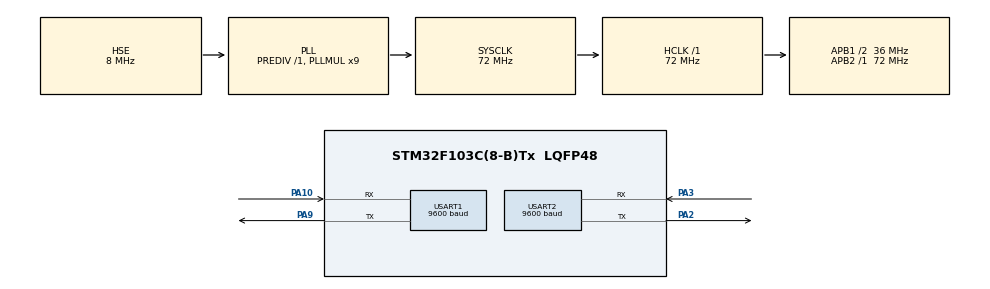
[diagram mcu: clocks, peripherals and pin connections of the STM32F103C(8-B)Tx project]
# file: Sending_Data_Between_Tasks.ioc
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FREERTOS.Queues01=myQueue01,16,OLED_Queue_t,0,Static,myQueue01Buffer,myQueue01ControlBlock
FREERTOS.Tasks01=defaultTask,24,128,StartDefaultTask,Default,NULL,Dynamic,NULL,NULL;UART_Task,24,128,Start_UART_Task,Default,NULL,Dynamic,NULL,NULL
Mcu.Family=STM32F1
Mcu.Name=STM32F103C(8-B)Tx
Mcu.Package=LQFP48
NVIC.PriorityGroup=NVIC_PRIORITYGROUP_4
NVIC.TIM4_IRQn=true\:15\:0\:false\:false\:true\:false\:false\:true\:true
NVIC.TimeBase=TIM4_IRQn
NVIC.TimeBaseIP=TIM4
PA10.Mode=Asynchronous
PA10.Signal=USART1_RX
PA13.Mode=Serial_Wire
PA13.Signal=SYS_JTMS-SWDIO
PA14.Mode=Serial_Wire
PA14.Signal=SYS_JTCK-SWCLK
PA2.Mode=Asynchronous
PA2.Signal=USART2_TX
PA3.Mode=Asynchronous
PA3.Signal=USART2_RX
PA9.Mode=Asynchronous
PA9.Signal=USART1_TX
PD0-OSC_IN.Mode=HSE-External-Oscillator
PD0-OSC_IN.Signal=RCC_OSC_IN
PD1-OSC_OUT.Mode=HSE-External-Oscillator
PD1-OSC_OUT.Signal=RCC_OSC_OUT
ProjectManager.HeapSize=0x200
ProjectManager.StackSize=0x400
ProjectManager.TargetToolchain=STM32CubeIDE
RCC.AHBFreq_Value=72000000
RCC.APB1CLKDivider=RCC_HCLK_DIV2
RCC.APB1Freq_Value=36000000
RCC.APB1TimFreq_Value=72000000
RCC.APB2Freq_Value=72000000
RCC.APB2TimFreq_Value=72000000
RCC.HCLKFreq_Value=72000000
RCC.PLLMUL=RCC_PLL_MUL9
RCC.PLLSourceVirtual=RCC_PLLSOURCE_HSE
RCC.SYSCLKFreq_VALUE=72000000
RCC.SYSCLKSource=RCC_SYSCLKSOURCE_PLLCLK
RCC.USBFreq_Value=72000000
USART1.BaudRate=9600
USART1.VirtualMode=VM_ASYNC
USART2.BaudRate=9600
USART2.VirtualMode=VM_ASYNC
VP_FREERTOS_VS_CMSIS_V2.Mode=CMSIS_V2
VP_SYS_VS_tim4.Mode=TIM4
board=custom

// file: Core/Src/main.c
/* USER CODE BEGIN Header */
/**
  ******************************************************************************
  * @file           : main.c
  * @brief          : Main program body
  ******************************************************************************
  * @attention
  *
  * Copyright (c) 2022 STMicroelectronics.
  * All rights reserved.
  *
  * This software is licensed under terms that can be found in the LICENSE file
  * in the root directory of this software component.
  * If no LICENSE file comes with this software, it is provided AS-IS.
  *
  ******************************************************************************
  */
/* USER CODE END Header */
#include "main.h"
#include "cmsis_os.h"

/* USER CODE BEGIN Includes */
#include <stdio.h>
#include <string.h>
#include <stdlib.h>
/* USER CODE END Includes */

typedef StaticQueue_t osStaticMessageQDef_t;
/* USER CODE BEGIN PTD */
typedef struct{
	char Buf[128];
} OLED_Queue_t;
/* USER CODE END PTD */

UART_HandleTypeDef huart1;
UART_HandleTypeDef huart2;

/* Definitions for defaultTask */
osThreadId_t defaultTaskHandle;
const osThreadAttr_t defaultTask_attributes = {
  .name = "defaultTask",
  .stack_size = 128 * 4,
  .priority = (osPriority_t) osPriorityNormal,
};
/* Definitions for UART_Task */
osThreadId_t UART_TaskHandle;
const osThreadAttr_t UART_Task_attributes = {
  .name = "UART_Task",
  .stack_size = 128 * 4,
  .priority = (osPriority_t) osPriorityNormal,
};
/* Definitions for myQueue01 */
osMessageQueueId_t myQueue01Handle;
uint8_t myQueue01Buffer[ 16 * sizeof( OLED_Queue_t ) ];
osStaticMessageQDef_t myQueue01ControlBlock;
const osMessageQueueAttr_t myQueue01_attributes = {
  .name = "myQueue01",
  .cb_mem = &myQueue01ControlBlock,
  .cb_size = sizeof(myQueue01ControlBlock),
  .mq_mem = &myQueue01Buffer,
  .mq_size = sizeof(myQueue01Buffer)
};

void SystemClock_Config(void);
static void MX_GPIO_Init(void);
static void MX_USART2_UART_Init(void);
static void MX_USART1_UART_Init(void);
void StartDefaultTask(void *argument);
void Start_UART_Task(void *argument);

int main(void)
{

  /* MCU Configuration--------------------------------------------------------*/

  /* Reset of all peripherals, Initializes the Flash interface and the Systick. */
  HAL_Init();

  /* Configure the system clock */
  SystemClock_Config();

  /* Initialize all configured peripherals */
  MX_GPIO_Init();
  MX_USART2_UART_Init();
  MX_USART1_UART_Init();

  /* Init scheduler */
  osKernelInitialize();

  /* Create the queue(s) */
  /* creation of myQueue01 */
  myQueue01Handle = osMessageQueueNew (16, sizeof(OLED_Queue_t), &myQueue01_attributes);

  /* Create the thread(s) */
  /* creation of defaultTask */
  defaultTaskHandle = osThreadNew(StartDefaultTask, NULL, &defaultTask_attributes);

  /* creation of UART_Task */
  UART_TaskHandle = osThreadNew(Start_UART_Task, NULL, &UART_Task_attributes);

  /* Start scheduler */
  osKernelStart();

  /* We should never get here as control is now taken by the scheduler */
  /* Infinite loop */
  while (1)
  {

  }
}

void SystemClock_Config(void)
{
  RCC_OscInitTypeDef RCC_OscInitStruct = {0};
  RCC_ClkInitTypeDef RCC_ClkInitStruct = {0};

  /** Initializes the RCC Oscillators according to the specified parameters
  * in the RCC_OscInitTypeDef structure.
  */
  RCC_OscInitStruct.OscillatorType = RCC_OSCILLATORTYPE_HSE;
  RCC_OscInitStruct.HSEState = RCC_HSE_ON;
  RCC_OscInitStruct.HSEPredivValue = RCC_HSE_PREDIV_DIV1;
  RCC_OscInitStruct.HSIState = RCC_HSI_ON;
  RCC_OscInitStruct.PLL.PLLState = RCC_PLL_ON;
  RCC_OscInitStruct.PLL.PLLSource = RCC_PLLSOURCE_HSE;
  RCC_OscInitStruct.PLL.PLLMUL = RCC_PLL_MUL9;
  if (HAL_RCC_OscConfig(&RCC_OscInitStruct) != HAL_OK)
  {
    Error_Handler();
  }

  /** Initializes the CPU, AHB and APB buses clocks
  */
  RCC_ClkInitStruct.ClockType = RCC_CLOCKTYPE_HCLK|RCC_CLOCKTYPE_SYSCLK
                              |RCC_CLOCKTYPE_PCLK1|RCC_CLOCKTYPE_PCLK2;
  RCC_ClkInitStruct.SYSCLKSource = RCC_SYSCLKSOURCE_PLLCLK;
  RCC_ClkInitStruct.AHBCLKDivider = RCC_SYSCLK_DIV1;
  RCC_ClkInitStruct.APB1CLKDivider = RCC_HCLK_DIV2;
  RCC_ClkInitStruct.APB2CLKDivider = RCC_HCLK_DIV1;

  if (HAL_RCC_ClockConfig(&RCC_ClkInitStruct, FLASH_LATENCY_2) != HAL_OK)
  {
    Error_Handler();
  }
}

static void MX_USART1_UART_Init(void)
{

  huart1.Instance = USART1;
  huart1.Init.BaudRate = 9600;
  huart1.Init.WordLength = UART_WORDLENGTH_8B;
  huart1.Init.StopBits = UART_STOPBITS_1;
  huart1.Init.Parity = UART_PARITY_NONE;
  huart1.Init.Mode = UART_MODE_TX_RX;
  huart1.Init.HwFlowCtl = UART_HWCONTROL_NONE;
  huart1.Init.OverSampling = UART_OVERSAMPLING_16;
  if (HAL_UART_Init(&huart1) != HAL_OK)
  {
    Error_Handler();
  }

}

static void MX_USART2_UART_Init(void)
{

  huart2.Instance = USART2;
  huart2.Init.BaudRate = 9600;
  huart2.Init.WordLength = UART_WORDLENGTH_8B;
  huart2.Init.StopBits = UART_STOPBITS_1;
  huart2.Init.Parity = UART_PARITY_NONE;
  huart2.Init.Mode = UART_MODE_TX_RX;
  huart2.Init.HwFlowCtl = UART_HWCONTROL_NONE;
  huart2.Init.OverSampling = UART_OVERSAMPLING_16;
  if (HAL_UART_Init(&huart2) != HAL_OK)
  {
    Error_Handler();
  }

}

static void MX_GPIO_Init(void)
{

  /* GPIO Ports Clock Enable */
  __HAL_RCC_GPIOD_CLK_ENABLE();
  __HAL_RCC_GPIOA_CLK_ENABLE();

}

void StartDefaultTask(void *argument)
{
  /* USER CODE BEGIN 5 */
	OLED_Queue_t msg;
	char STM32Req[]="STM32 NEW request: \r\n";
  /* Infinite loop */
  for(;;)
  {
	  //strcpy(msg.Buf, "Yes! \r\n");
	  strcpy(msg.Buf, STM32Req);
	  osMessageQueuePut(myQueue01Handle, &msg, 0, osWaitForever);
	  osDelay(1000);
  }
  /* USER CODE END 5 */
}

void Start_UART_Task(void *argument)
{
  /* USER CODE BEGIN Start_UART_Task */

	OLED_Queue_t msg;
  /* Infinite loop */
  for(;;)
  {
		osMessageQueueGet(myQueue01Handle, &msg, 0, osWaitForever);
		HAL_UART_Transmit(&huart2, (uint8_t*)msg.Buf, strlen(msg.Buf), osWaitForever);
		osDelay(1);
  }
  /* USER CODE END Start_UART_Task */
}

void HAL_TIM_PeriodElapsedCallback(TIM_HandleTypeDef *htim)
{
  if (htim->Instance == TIM4) {
    HAL_IncTick();
  }
}

void Error_Handler(void)
{
  __disable_irq();
  while (1)
  {
  }
}
